# AT90PWM3 register map
Vendor: Atmel; File version: 1.0
CPU: other r0p0, little endian, no MPU, no FPU, 4 interrupt priority bits
Registers are 8-bit, read-write, reset 0x0 unless marked. A register's access mark holds for its fields unless they carry their own. Offsets are from the block's base; [hi:lo] are bit positions; {n}, {i} and the like mark numbered series.

## ADC — Analog-to-Digital Converter
Base 0x00800076
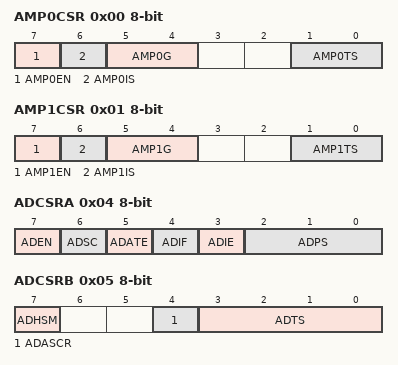
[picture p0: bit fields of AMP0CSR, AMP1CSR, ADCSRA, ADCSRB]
0x00 AMP0CSR
  [7] AMP0EN, [6] AMP0IS, [5:4] AMP0G, [1:0] AMP0TS
0x01 AMP1CSR
  [7] AMP1EN, [6] AMP1IS, [5:4] AMP1G, [1:0] AMP1TS
0x02 ADC 16-bit (reset mask 0xFF) — ADC Data Register Bytes
  [15:0] ADC — ADC Data Register
0x04 ADCSRA — The ADC Control and Status register (read-only for debugger)
  [7] ADEN — ADC Enable
  [6] ADSC — ADC Start Conversion
  [5] ADATE — ADC Auto Trigger Enable
  [4] ADIF — ADC Interrupt Flag
  [3] ADIE — ADC Interrupt Enable
  [2:0] ADPS — ADC Prescaler Select Bits
0x05 ADCSRB — ADC Control and Status Register B
  [7] ADHSM — ADC High Speed Mode
  [4] ADASCR — Amplified Channel Start Conversion
  [3:0] ADTS — ADC Auto Trigger Source
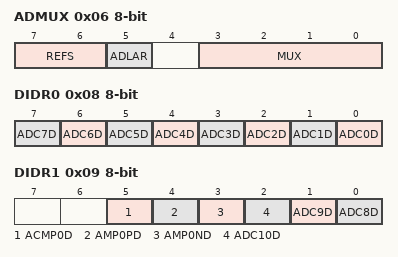
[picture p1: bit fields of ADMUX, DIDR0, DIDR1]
0x06 ADMUX — The ADC multiplexer Selection Register
  [7:6] REFS — Reference Selection Bits
    0=AREF_INTERNAL_VREF_TURNED_OFF; 1=AVCC_WITH_EXTERNAL_CAPACITOR_AT_AREF_PIN; 3=INTERNAL_2_56V_VOLTAGE_REFERENCE_WITH_EXTERNAL_CAPACITOR_AT_AREF_PIN
  [5] ADLAR — Left Adjust Result
  [3:0] MUX — Analog Channel and Gain Selection Bits
0x08 DIDR0 — Digital Input Disable Register 0
  [n] ADC{n}D (n=0..7)
0x09 DIDR1 — Digital Input Disable Register 1
  [5] ACMP0D, [4] AMP0PD, [3] AMP0ND, [2] ADC10D, [1] ADC9D, [0] ADC8D

## BOOT_LOAD — Bootloader
Base 0x00800057
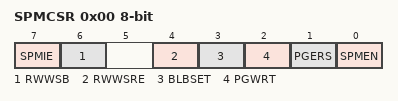
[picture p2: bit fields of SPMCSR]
0x00 SPMCSR — Store Program Memory Control Register
  [7] SPMIE — SPM Interrupt Enable
  [6] RWWSB — Read While Write Section Busy
  [4] RWWSRE — Read While Write section read enable
  [3] BLBSET — Boot Lock Bit Set
  [2] PGWRT — Page Write
  [1] PGERS — Page Erase
  [0] SPMEN — Store Program Memory Enable

## CPU — CPU Registers
Base 0x00800039
0x00 GPIOR1 — General Purpose IO Register 1
  [7:0] GPIOR — General Purpose IO Register 1 bis
0x01 GPIOR2 — General Purpose IO Register 2
  [7:0] GPIOR — General Purpose IO Register 2 bis
0x02 GPIOR3 — General Purpose IO Register 3
  [7:0] GPIOR — General Purpose IO Register 3 bis
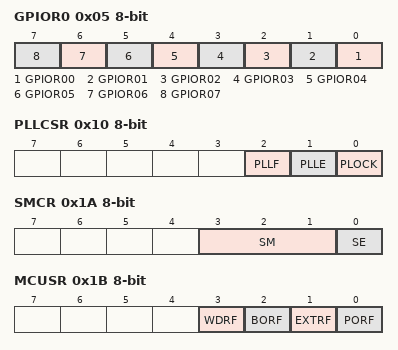
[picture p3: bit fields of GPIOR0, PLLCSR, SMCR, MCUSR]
0x05 GPIOR0 — General Purpose IO Register 0
  [n] GPIOR{n:02} (n=0..7) — General Purpose IO Register 0 bit {n}
0x10 PLLCSR — PLL Control And Status Register
  [2] PLLF — PLL Factor
  [1] PLLE — PLL Enable
  [0] PLOCK — PLL Lock Detector
0x1A SMCR — Sleep Mode Control Register
  [3:1] SM — Sleep Mode Select bits
    0=IDLE; 1=ADC (ADC Noise Reduction (If Available)); 2=PDOWN (Power Down); 6=STDBY (Standby)
  [0] SE — Sleep Enable
0x1B MCUSR — MCU Status Register
  [3] WDRF — Watchdog Reset Flag
  [2] BORF — Brown-out Reset Flag
  [1] EXTRF — External Reset Flag
  [0] PORF — Power-on reset flag
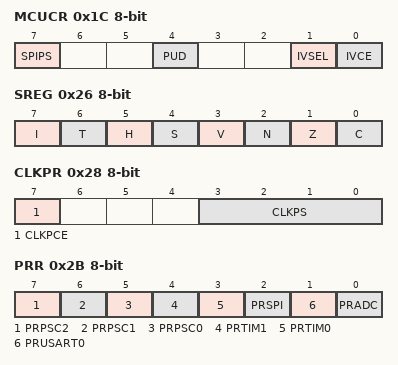
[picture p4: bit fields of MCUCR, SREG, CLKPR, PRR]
0x1C MCUCR — MCU Control Register
  [7] SPIPS — SPI Pin Select
  [4] PUD — Pull-up disable
  [1] IVSEL — Interrupt Vector Select
  [0] IVCE — Interrupt Vector Change Enable
0x24 SP 16-bit (reset mask 0xFF) — Stack Pointer
0x26 SREG — Status Register
  [7] I — Global Interrupt Enable
  [6] T — Bit Copy Storage
  [5] H — Half Carry Flag
  [4] S — Sign Bit
  [3] V — Two's Complement Overflow Flag
  [2] N — Negative Flag
  [1] Z — Zero Flag
  [0] C — Carry Flag
0x28 CLKPR
  [7] CLKPCE
  [3:0] CLKPS
    0=1; 1=2; 2=4; 3=8; 4=16; 5=32; 6=64; 7=128; 8=256
0x2B PRR — Power Reduction Register
  [7] PRPSC2 — Power Reduction PSC2
  [6] PRPSC1 — Power Reduction PSC1
  [5] PRPSC0 — Power Reduction PSC0
  [4] PRTIM1 — Power Reduction Timer/Counter1
  [3] PRTIM0 — Power Reduction Timer/Counter0
  [2] PRSPI — Power Reduction Serial Peripheral Interface
  [1] PRUSART0 — Power Reduction USART
  [0] PRADC — Power Reduction ADC
0x2D OSCCAL — Oscillator Calibration Value (read-only for debugger)
  [7:0] OSCCAL — Oscillator Calibration

## DAC — Digital-to-Analog Converter
Base 0x008000AA
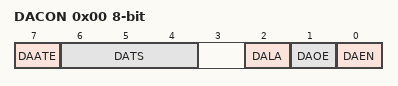
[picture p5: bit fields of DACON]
0x00 DACON — DAC Control Register
  [7] DAATE — DAC Auto Trigger Enable Bit
  [6:4] DATS — DAC Trigger Selection Bits
    0=ANALOG_COMPARATOR_0; 1=ANALOG_COMPARATOR_1; 2=EXTERNAL_INTERRUPT_REQUEST_0; 3=TIMER_COUNTER0_COMPARE_MATCH_A; 4=TIMER_COUNTER0_OVERFLOW; 5=TIMER_COUNTER1_COMPARE_MATCH_B; 6=TIMER_COUNTER1_OVERFLOW; 7=TIMER_COUNTER1_CAPTURE_EVENT
  [2] DALA — DAC Left Adjust
  [1] DAOE — DAC Output Enable
  [0] DAEN — DAC Enable Bit
0x01 DAC 16-bit (reset mask 0xFF) — DAC Data Register (write-only for debugger)
  [15:0] DAC — DAC Data Register Bits
